AUTOSAR XML (schema 4.0)
package /ADAS_Components
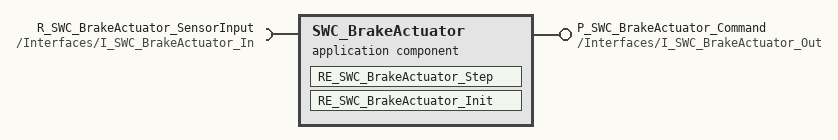
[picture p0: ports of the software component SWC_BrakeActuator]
  application sw component type SWC_BrakeActuator  # AUTOSAR Application SWC SWC_BrakeActuator for ADAS control sub-system
    provide port P_SWC_BrakeActuator_Command: provided-interface=/Interfaces/I_SWC_BrakeActuator_Out
    require port R_SWC_BrakeActuator_SensorInput: required-interface=/Interfaces/I_SWC_BrakeActuator_In
    behavior SWC_BrakeActuator_Behavior
      runnable RE_SWC_BrakeActuator_Step: symbol=SWC_BrakeActuator_Step
      runnable RE_SWC_BrakeActuator_Init: symbol=SWC_BrakeActuator_Init
  sender receiver interface I_SWC_BrakeActuator_Out  # Sender Receiver Interface for SWC_BrakeActuator outputs
    data DE_SWC_BrakeActuator_Signal: type=/AUTOSAR/Platform/uint32
  sender receiver interface I_SWC_BrakeActuator_In  # Sender Receiver Interface for SWC_BrakeActuator inputs
    data DE_SWC_BrakeActuator_RawData: type=/AUTOSAR/Platform/uint16
